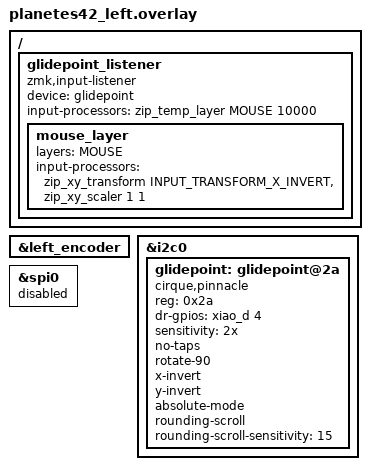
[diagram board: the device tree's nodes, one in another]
#include "planetes42.dtsi"
#define MOUSE 9

/ {
     // pointing device
    glidepoint_listener {
        compatible = "zmk,input-listener";
        device = <&glidepoint>;
        input-processors = <&zip_temp_layer MOUSE 10000>;

        mouse_layer {
          layers = <MOUSE>;

          input-processors = <&zip_xy_transform INPUT_TRANSFORM_X_INVERT>,<&zip_xy_scaler 1 1>;
        };
    };
};

&left_encoder {
    status = "okay";
};

&i2c0 {
    status = "okay";

    glidepoint: glidepoint@2a {
        compatible = "cirque,pinnacle";
        status = "okay";
        reg = <0x2a>;
        dr-gpios = <&xiao_d 4 (GPIO_ACTIVE_HIGH)>;

        sensitivity = "2x";
        /* sleep; */
        no-taps;
        rotate-90;
        x-invert;
        y-invert;
        absolute-mode;
        rounding-scroll;
        rounding-scroll-sensitivity = <15>;
    };
};

&spi0 {
  status = "disabled";
};

